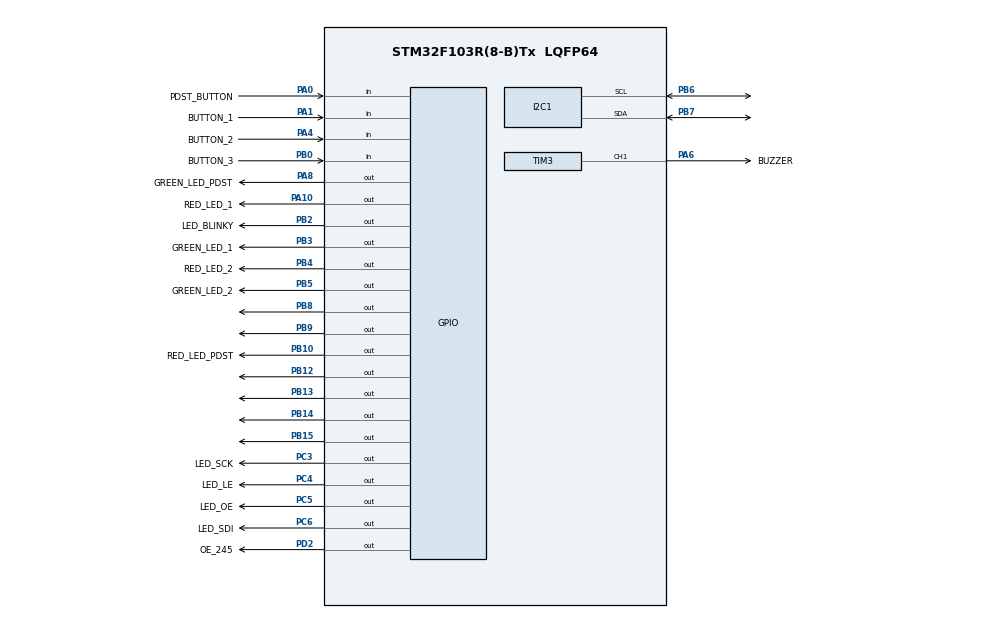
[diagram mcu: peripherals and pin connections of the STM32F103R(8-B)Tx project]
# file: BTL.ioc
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Mcu.Family=STM32F1
Mcu.Name=STM32F103R(8-B)Tx
Mcu.Package=LQFP64
NVIC.PriorityGroup=NVIC_PRIORITYGROUP_4
NVIC.TIM3_IRQn=true\:0\:0\:false\:false\:true\:true\:true\:true
PA0-WKUP.GPIO_Label=PDST_BUTTON
PA0-WKUP.Signal=GPIO_Input
PA1.GPIO_Label=BUTTON_1
PA1.GPIO_PuPd=GPIO_PULLUP
PA1.Signal=GPIO_Input
PA10.GPIO_Label=RED_LED_1
PA10.Signal=GPIO_Output
PA13.Mode=Serial_Wire
PA13.Signal=SYS_JTMS-SWDIO
PA14.Mode=Serial_Wire
PA14.Signal=SYS_JTCK-SWCLK
PA4.GPIO_Label=BUTTON_2
PA4.GPIO_PuPd=GPIO_PULLUP
PA4.Signal=GPIO_Input
PA6.GPIO_Label=BUZZER
PA6.Signal=S_TIM3_CH1
PA8.GPIO_Label=GREEN_LED_PDST
PA8.Signal=GPIO_Output
PB0.GPIO_Label=BUTTON_3
PB0.GPIO_PuPd=GPIO_PULLUP
PB0.Signal=GPIO_Input
PB10.GPIO_Label=RED_LED_PDST
PB10.Signal=GPIO_Output
PB12.Signal=GPIO_Output
PB13.Signal=GPIO_Output
PB14.Signal=GPIO_Output
PB15.Signal=GPIO_Output
PB2.GPIO_Label=LED_BLINKY
PB2.Signal=GPIO_Output
PB3.GPIO_Label=GREEN_LED_1
PB3.Signal=GPIO_Output
PB4.GPIO_Label=RED_LED_2
PB4.Signal=GPIO_Output
PB5.GPIO_Label=GREEN_LED_2
PB5.Signal=GPIO_Output
PB6.Mode=I2C
PB6.Signal=I2C1_SCL
PB7.Mode=I2C
PB7.Signal=I2C1_SDA
PB8.Signal=GPIO_Output
PB9.Signal=GPIO_Output
PC3.GPIO_Label=LED_SCK
PC3.Signal=GPIO_Output
PC4.GPIO_Label=LED_LE
PC4.Signal=GPIO_Output
PC5.GPIO_Label=LED_OE
PC5.Signal=GPIO_Output
PC6.GPIO_Label=LED_SDI
PC6.Signal=GPIO_Output
PD2.GPIO_Label=OE_245
PD2.Signal=GPIO_Output
ProjectManager.HeapSize=0x200
ProjectManager.StackSize=0x400
ProjectManager.TargetToolchain=STM32CubeIDE
RCC.APB1Freq_Value=8000000
RCC.APB2Freq_Value=8000000
SH.S_TIM3_CH1.0=TIM3_CH1,Output Compare1 CH1
TIM3.Channel-Output\ Compare1\ CH1=TIM_CHANNEL_1
TIM3.Period=9
TIM3.Prescaler=7999
VP_TIM3_VS_ClockSourceINT.Mode=Internal
board=custom

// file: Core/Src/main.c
/* USER CODE BEGIN Header */
/**
  ******************************************************************************
  * @file           : main.c
  * @brief          : Main program body
  ******************************************************************************
  * @attention
  *
  * <h2><center>&copy; Copyright (c) 2022 STMicroelectronics.
  * All rights reserved.</center></h2>
  *
  * This software component is licensed by ST under BSD 3-Clause license,
  * the "License"; You may not use this file except in compliance with the
  * License. You may obtain a copy of the License at:
  *                        opensource.org/licenses/BSD-3-Clause
  *
  ******************************************************************************
  */
/* USER CODE END Header */
#include "main.h"

/* USER CODE BEGIN Includes */
#include "led-display.h"
#include "software_timer.h"
#include "global.h"
#include "lcd.h"
#include "fsm.h"
/* USER CODE END Includes */

I2C_HandleTypeDef hi2c1;

TIM_HandleTypeDef htim3;

void SystemClock_Config(void);
static void MX_GPIO_Init(void);
static void MX_TIM3_Init(void);
static void MX_I2C1_Init(void);

int main(void)
{

  /* MCU Configuration--------------------------------------------------------*/

  /* Reset of all peripherals, Initializes the Flash interface and the Systick. */
  HAL_Init();

  /* Configure the system clock */
  SystemClock_Config();

  /* Initialize all configured peripherals */
  MX_GPIO_Init();
  MX_TIM3_Init();
  MX_I2C1_Init();
  /* USER CODE BEGIN 2 */
  HAL_TIM_Base_Start_IT(&htim3);
  HAL_GPIO_WritePin(OE_245_GPIO_Port, OE_245_Pin, RESET);
  outputEnable();

  Lcd_Initialization();
  /* USER CODE END 2 */

  /* Infinite loop */
  while (1)
  {
//	  for (int i = 1; i < 5; i++){
//		  HAL_GPIO_TogglePin(LED_BLINKY_GPIO_Port, LED_BLINKY_Pin);
//		  enableLedPannel(i);
//		  HAL_Delay(1000);
//	  }
	LCD_Testing();
	fsm();
  }
}

void SystemClock_Config(void)
{
  RCC_OscInitTypeDef RCC_OscInitStruct = {0};
  RCC_ClkInitTypeDef RCC_ClkInitStruct = {0};

  /** Initializes the RCC Oscillators according to the specified parameters
  * in the RCC_OscInitTypeDef structure.
  */
  RCC_OscInitStruct.OscillatorType = RCC_OSCILLATORTYPE_HSI;
  RCC_OscInitStruct.HSIState = RCC_HSI_ON;
  RCC_OscInitStruct.HSICalibrationValue = RCC_HSICALIBRATION_DEFAULT;
  RCC_OscInitStruct.PLL.PLLState = RCC_PLL_NONE;
  if (HAL_RCC_OscConfig(&RCC_OscInitStruct) != HAL_OK)
  {
    Error_Handler();
  }

  /** Initializes the CPU, AHB and APB buses clocks
  */
  RCC_ClkInitStruct.ClockType = RCC_CLOCKTYPE_HCLK|RCC_CLOCKTYPE_SYSCLK
                              |RCC_CLOCKTYPE_PCLK1|RCC_CLOCKTYPE_PCLK2;
  RCC_ClkInitStruct.SYSCLKSource = RCC_SYSCLKSOURCE_HSI;
  RCC_ClkInitStruct.AHBCLKDivider = RCC_SYSCLK_DIV1;
  RCC_ClkInitStruct.APB1CLKDivider = RCC_HCLK_DIV1;
  RCC_ClkInitStruct.APB2CLKDivider = RCC_HCLK_DIV1;

  if (HAL_RCC_ClockConfig(&RCC_ClkInitStruct, FLASH_LATENCY_0) != HAL_OK)
  {
    Error_Handler();
  }
}

static void MX_I2C1_Init(void)
{

  hi2c1.Instance = I2C1;
  hi2c1.Init.ClockSpeed = 100000;
  hi2c1.Init.DutyCycle = I2C_DUTYCYCLE_2;
  hi2c1.Init.OwnAddress1 = 0;
  hi2c1.Init.AddressingMode = I2C_ADDRESSINGMODE_7BIT;
  hi2c1.Init.DualAddressMode = I2C_DUALADDRESS_DISABLE;
  hi2c1.Init.OwnAddress2 = 0;
  hi2c1.Init.GeneralCallMode = I2C_GENERALCALL_DISABLE;
  hi2c1.Init.NoStretchMode = I2C_NOSTRETCH_DISABLE;
  if (HAL_I2C_Init(&hi2c1) != HAL_OK)
  {
    Error_Handler();
  }

}

static void MX_TIM3_Init(void)
{

  TIM_ClockConfigTypeDef sClockSourceConfig = {0};
  TIM_MasterConfigTypeDef sMasterConfig = {0};
  TIM_OC_InitTypeDef sConfigOC = {0};

  htim3.Instance = TIM3;
  htim3.Init.Prescaler = 7999;
  htim3.Init.CounterMode = TIM_COUNTERMODE_UP;
  htim3.Init.Period = 9;
  htim3.Init.ClockDivision = TIM_CLOCKDIVISION_DIV1;
  htim3.Init.AutoReloadPreload = TIM_AUTORELOAD_PRELOAD_DISABLE;
  if (HAL_TIM_Base_Init(&htim3) != HAL_OK)
  {
    Error_Handler();
  }
  sClockSourceConfig.ClockSource = TIM_CLOCKSOURCE_INTERNAL;
  if (HAL_TIM_ConfigClockSource(&htim3, &sClockSourceConfig) != HAL_OK)
  {
    Error_Handler();
  }
  if (HAL_TIM_OC_Init(&htim3) != HAL_OK)
  {
    Error_Handler();
  }
  sMasterConfig.MasterOutputTrigger = TIM_TRGO_RESET;
  sMasterConfig.MasterSlaveMode = TIM_MASTERSLAVEMODE_DISABLE;
  if (HAL_TIMEx_MasterConfigSynchronization(&htim3, &sMasterConfig) != HAL_OK)
  {
    Error_Handler();
  }
  sConfigOC.OCMode = TIM_OCMODE_TIMING;
  sConfigOC.Pulse = 0;
  sConfigOC.OCPolarity = TIM_OCPOLARITY_HIGH;
  sConfigOC.OCFastMode = TIM_OCFAST_DISABLE;
  if (HAL_TIM_OC_ConfigChannel(&htim3, &sConfigOC, TIM_CHANNEL_1) != HAL_OK)
  {
    Error_Handler();
  }
  HAL_TIM_MspPostInit(&htim3);

}

static void MX_GPIO_Init(void)
{
  GPIO_InitTypeDef GPIO_InitStruct = {0};

  /* GPIO Ports Clock Enable */
  __HAL_RCC_GPIOC_CLK_ENABLE();
  __HAL_RCC_GPIOA_CLK_ENABLE();
  __HAL_RCC_GPIOB_CLK_ENABLE();
  __HAL_RCC_GPIOD_CLK_ENABLE();

  /*Configure GPIO pin Output Level */
  HAL_GPIO_WritePin(GPIOC, LED_SCK_Pin|LED_LE_Pin|LED_OE_Pin|LED_SDI_Pin, GPIO_PIN_RESET);

  /*Configure GPIO pin Output Level */
  HAL_GPIO_WritePin(GPIOB, LED_BLINKY_Pin|RED_LED_PDST_Pin|GPIO_PIN_12|GPIO_PIN_13
                          |GPIO_PIN_14|GPIO_PIN_15|GREEN_LED_1_Pin|RED_LED_2_Pin
                          |GREEN_LED_2_Pin|GPIO_PIN_8|GPIO_PIN_9, GPIO_PIN_RESET);

  /*Configure GPIO pin Output Level */
  HAL_GPIO_WritePin(GPIOA, GREEN_LED_PDST_Pin|RED_LED_1_Pin, GPIO_PIN_RESET);

  /*Configure GPIO pin Output Level */
  HAL_GPIO_WritePin(OE_245_GPIO_Port, OE_245_Pin, GPIO_PIN_RESET);

  /*Configure GPIO pins : LED_SCK_Pin LED_LE_Pin LED_OE_Pin LED_SDI_Pin */
  GPIO_InitStruct.Pin = LED_SCK_Pin|LED_LE_Pin|LED_OE_Pin|LED_SDI_Pin;
  GPIO_InitStruct.Mode = GPIO_MODE_OUTPUT_PP;
  GPIO_InitStruct.Pull = GPIO_NOPULL;
  GPIO_InitStruct.Speed = GPIO_SPEED_FREQ_LOW;
  HAL_GPIO_Init(GPIOC, &GPIO_InitStruct);

  /*Configure GPIO pin : PDST_BUTTON_Pin */
  GPIO_InitStruct.Pin = PDST_BUTTON_Pin;
  GPIO_InitStruct.Mode = GPIO_MODE_INPUT;
  GPIO_InitStruct.Pull = GPIO_NOPULL;
  HAL_GPIO_Init(PDST_BUTTON_GPIO_Port, &GPIO_InitStruct);

  /*Configure GPIO pins : BUTTON_1_Pin BUTTON_2_Pin */
  GPIO_InitStruct.Pin = BUTTON_1_Pin|BUTTON_2_Pin;
  GPIO_InitStruct.Mode = GPIO_MODE_INPUT;
  GPIO_InitStruct.Pull = GPIO_PULLUP;
  HAL_GPIO_Init(GPIOA, &GPIO_InitStruct);

  /*Configure GPIO pin : BUTTON_3_Pin */
  GPIO_InitStruct.Pin = BUTTON_3_Pin;
  GPIO_InitStruct.Mode = GPIO_MODE_INPUT;
  GPIO_InitStruct.Pull = GPIO_PULLUP;
  HAL_GPIO_Init(BUTTON_3_GPIO_Port, &GPIO_InitStruct);

  /*Configure GPIO pins : LED_BLINKY_Pin RED_LED_PDST_Pin PB12 PB13
                           PB14 PB15 GREEN_LED_1_Pin RED_LED_2_Pin
                           GREEN_LED_2_Pin PB8 PB9 */
  GPIO_InitStruct.Pin = LED_BLINKY_Pin|RED_LED_PDST_Pin|GPIO_PIN_12|GPIO_PIN_13
                          |GPIO_PIN_14|GPIO_PIN_15|GREEN_LED_1_Pin|RED_LED_2_Pin
                          |GREEN_LED_2_Pin|GPIO_PIN_8|GPIO_PIN_9;
  GPIO_InitStruct.Mode = GPIO_MODE_OUTPUT_PP;
  GPIO_InitStruct.Pull = GPIO_NOPULL;
  GPIO_InitStruct.Speed = GPIO_SPEED_FREQ_LOW;
  HAL_GPIO_Init(GPIOB, &GPIO_InitStruct);

  /*Configure GPIO pins : GREEN_LED_PDST_Pin RED_LED_1_Pin */
  GPIO_InitStruct.Pin = GREEN_LED_PDST_Pin|RED_LED_1_Pin;
  GPIO_InitStruct.Mode = GPIO_MODE_OUTPUT_PP;
  GPIO_InitStruct.Pull = GPIO_NOPULL;
  GPIO_InitStruct.Speed = GPIO_SPEED_FREQ_LOW;
  HAL_GPIO_Init(GPIOA, &GPIO_InitStruct);

  /*Configure GPIO pin : OE_245_Pin */
  GPIO_InitStruct.Pin = OE_245_Pin;
  GPIO_InitStruct.Mode = GPIO_MODE_OUTPUT_PP;
  GPIO_InitStruct.Pull = GPIO_NOPULL;
  GPIO_InitStruct.Speed = GPIO_SPEED_FREQ_LOW;
  HAL_GPIO_Init(OE_245_GPIO_Port, &GPIO_InitStruct);

}

/* USER CODE BEGIN 4 */
void HAL_TIM_PeriodElapsedCallback(TIM_HandleTypeDef *htim){
	timer_run();
}
/* USER CODE END 4 */

void Error_Handler(void)
{
  __disable_irq();
  while (1)
  {
  }
}
